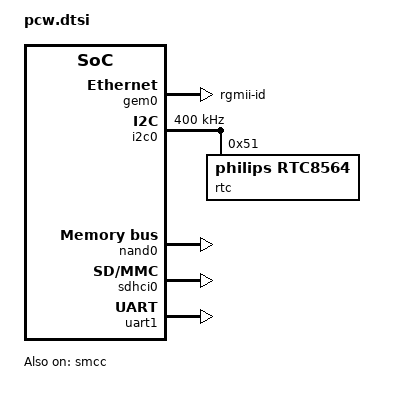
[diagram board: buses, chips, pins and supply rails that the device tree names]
/*
 * CAUTION: This file is automatically generated by Xilinx.
 * Version: XSCT 2019.1
 * Today is: Thu Sep  5 17:37:06 2019
 */


/ {
	cpus {
		cpu@0 {
			operating-points = <666666 1000000 333333 1000000>;
		};
	};
};
&gem0 {
	phy-mode = "rgmii-id";
	status = "okay";
	xlnx,ptp-enet-clock = <0x69f6bcb>;
};
&i2c0 {
	clock-frequency = <400000>;
	status = "okay";
	rtc@51 {
		compatible = "philips,rtc8564";
		#address-cells = <0x1>;
		#size-cells = <0x0>;
		reg = <0x51>;
	};
};
&intc {
	num_cpus = <2>;
	num_interrupts = <96>;
};
&nand0 {
	arm,nand-cycle-t0 = <0x5>;
	arm,nand-cycle-t1 = <0x5>;
	arm,nand-cycle-t2 = <0x2>;
	arm,nand-cycle-t3 = <0x3>;
	arm,nand-cycle-t4 = <0x1>;
	arm,nand-cycle-t5 = <0x1>;
	arm,nand-cycle-t6 = <0x2>;
	nand-bus-width = <8>;
	status = "okay";
};
&sdhci0 {
	status = "okay";
	xlnx,has-cd = <0x1>;
	xlnx,has-power = <0x0>;
	xlnx,has-wp = <0x1>;
};
&smcc {
	status = "okay";
};
&uart1 {
	cts-override ;
	device_type = "serial";
	port-number = <0>;
	status = "okay";
};
&clkc {
	fclk-enable = <0x3>;
	ps-clk-frequency = <33333333>;
};
